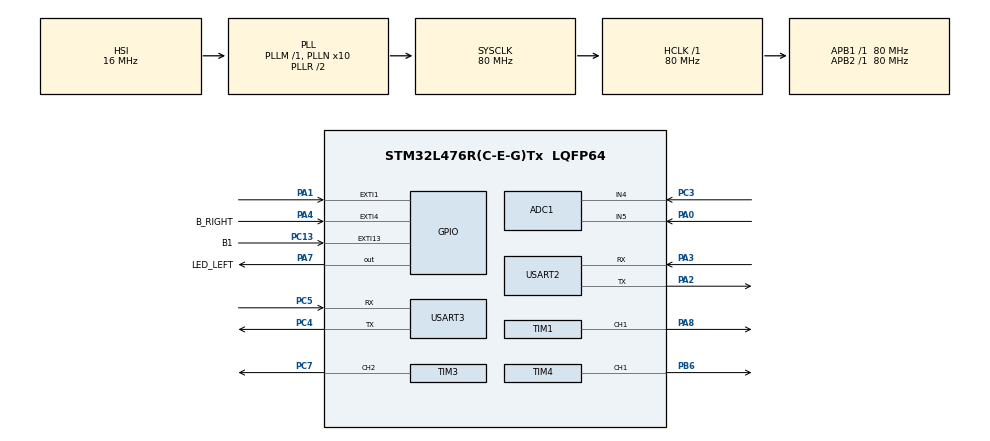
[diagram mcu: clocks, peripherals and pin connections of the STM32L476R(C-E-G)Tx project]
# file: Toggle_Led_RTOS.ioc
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ADC1.Channel-1\#ChannelRegularConversion=ADC_CHANNEL_4
ADC1.ContinuousConvMode=ENABLE
ADC1.NbrOfConversionFlag=1
ADC1.OffsetNumber-1\#ChannelRegularConversion=ADC_OFFSET_NONE
ADC1.Rank-1\#ChannelRegularConversion=1
ADC1.SamplingTime-1\#ChannelRegularConversion=ADC_SAMPLETIME_2CYCLES_5
ADC1.master=1
FREERTOS.Tasks01=defaultTask,24,128,StartDefaultTask,Default,NULL,Dynamic,NULL,NULL
Mcu.Family=STM32L4
Mcu.Name=STM32L476R(C-E-G)Tx
Mcu.Package=LQFP64
NVIC.ADC1_2_IRQn=true\:5\:0\:false\:false\:true\:true\:true\:true\:true
NVIC.EXTI15_10_IRQn=true\:5\:0\:false\:false\:true\:true\:true\:true\:true
NVIC.EXTI1_IRQn=true\:5\:0\:false\:false\:true\:true\:true\:true\:true
NVIC.EXTI4_IRQn=true\:5\:0\:false\:false\:true\:true\:true\:true\:true
NVIC.PriorityGroup=NVIC_PRIORITYGROUP_4
NVIC.USART2_IRQn=true\:5\:0\:false\:false\:true\:true\:true\:true\:true
NVIC.USART3_IRQn=true\:5\:0\:false\:false\:true\:true\:true\:true\:true
PA0.Signal=ADCx_IN5
PA1.Signal=GPXTI1
PA2.Mode=Asynchronous
PA2.Signal=USART2_TX
PA3.Mode=Asynchronous
PA3.Signal=USART2_RX
PA4.GPIO_Label=B_RIGHT
PA4.Signal=GPXTI4
PA7.GPIO_Label=LED_LEFT
PA7.PinState=GPIO_PIN_SET
PA7.Signal=GPIO_Output
PA8.Signal=S_TIM1_CH1
PB6.Signal=S_TIM4_CH1
PC13.GPIO_Label=B1
PC13.Signal=GPXTI13
PC3.Signal=ADCx_IN4
PC4.Mode=Asynchronous
PC4.Signal=USART3_TX
PC5.Mode=Asynchronous
PC5.Signal=USART3_RX
PC7.Signal=S_TIM3_CH2
ProjectManager.HeapSize=0x200
ProjectManager.StackSize=0x400
ProjectManager.TargetToolchain=STM32CubeIDE
RCC.ADCFreq_Value=64000000
RCC.AHBFreq_Value=80000000
RCC.APB1Freq_Value=80000000
RCC.APB1TimFreq_Value=80000000
RCC.APB2Freq_Value=80000000
RCC.APB2TimFreq_Value=80000000
RCC.CortexFreq_Value=80000000
RCC.HCLKFreq_Value=80000000
RCC.HSE_VALUE=8000000
RCC.HSI_VALUE=16000000
RCC.LSE_VALUE=32768
RCC.MSI_VALUE=4000000
RCC.PLLN=10
RCC.PLLSourceVirtual=RCC_PLLSOURCE_HSI
RCC.SYSCLKFreq_VALUE=80000000
RCC.SYSCLKSource=RCC_SYSCLKSOURCE_PLLCLK
RCC.USBFreq_Value=64000000
RCC.VCOOutputFreq_Value=160000000
SH.ADCx_IN4.0=ADC1_IN4,IN4-Single-Ended
SH.ADCx_IN5.0=ADC1_IN5,IN5-Single-Ended
SH.S_TIM1_CH1.0=TIM1_CH1,PWM Generation1 CH1
SH.S_TIM3_CH2.0=TIM3_CH2,PWM Generation2 CH2
SH.S_TIM4_CH1.0=TIM4_CH1,PWM Generation1 CH1
TIM1.Channel-PWM\ Generation1\ CH1=TIM_CHANNEL_1
TIM16.Period=10000-1
TIM16.Prescaler=8000-1
TIM3.Channel-PWM\ Generation2\ CH2=TIM_CHANNEL_2
TIM4.Channel-PWM\ Generation1\ CH1=TIM_CHANNEL_1
USART2.VirtualMode-Asynchronous=VM_ASYNC
USART3.VirtualMode-Asynchronous=VM_ASYNC
VP_FREERTOS_VS_CMSIS_V2.Mode=CMSIS_V2
VP_TIM16_VS_ClockSourceINT.Mode=Enable_Timer
board=custom

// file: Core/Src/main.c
/* USER CODE BEGIN Header */
/**
  ******************************************************************************
  * @file           : main.c
  * @brief          : Main program body
  ******************************************************************************
  * @attention
  *
  * Copyright (c) 2024 STMicroelectronics.
  * All rights reserved.
  *
  * This software is licensed under terms that can be found in the LICENSE file
  * in the root directory of this software component.
  * If no LICENSE file comes with this software, it is provided AS-IS.
  *
  ******************************************************************************
  */
/* USER CODE END Header */
#include "main.h"
#include "cmsis_os.h"

/* USER CODE BEGIN Includes */
#include "string.h"

#include <stdio.h>
/* USER CODE END Includes */

/* USER CODE BEGIN PD */

#define REFERENCE_VOLTAGE 1.6f
#define NUM_INTERVALS     8

// Si quieres que sea variable en tiempo de ejecución:
// static float referenceVoltage = 2.5f;

/* USER CODE END PD */

/* USER CODE BEGIN PM */
/* Handles de periféricos */
ADC_HandleTypeDef hadc1;
UART_HandleTypeDef huart2;

/* USER CODE END PM */

ADC_HandleTypeDef hadc1;

TIM_HandleTypeDef htim1;
TIM_HandleTypeDef htim3;
TIM_HandleTypeDef htim4;
TIM_HandleTypeDef htim16;

UART_HandleTypeDef huart2;
UART_HandleTypeDef huart3;

/* Definitions for defaultTask */
osThreadId_t defaultTaskHandle;
const osThreadAttr_t defaultTask_attributes = {
  .name = "defaultTask",
  .stack_size = 128 * 4,
  .priority = (osPriority_t) osPriorityNormal,
};

void SystemClock_Config(void);
static void MX_GPIO_Init(void);
static void MX_ADC1_Init(void);
static void MX_USART2_UART_Init(void);
static void MX_USART3_UART_Init(void);
static void MX_TIM4_Init(void);
static void MX_TIM16_Init(void);
static void MX_TIM3_Init(void);
static void MX_TIM1_Init(void);
void StartDefaultTask(void *argument);

/* USER CODE BEGIN PFP */

/* Prototipos de funciones */
void HAL_GPIO_EXTI_Callback(uint16_t GPIO_Pin);
void Read_ADC(uint32_t *adc_value, float *voltage);
void Update_PWM_DutyCycle(float voltage);

/* Declaración de tareas */
void Task_ADC_Read_And_Update_PWM(void *argument);

/* Variables globales */
volatile uint8_t adc_task_active = 0; // Bandera para controlar el estado de la tarea (1 = activa, 0 = inactiva)
volatile uint32_t debounce_time = 0;  // Tiempo para el filtro de rebote

/* Declaración del handle de la tarea */
osThreadId_t adc_task_handle;

/* USER CODE END PFP */

int main(void)
{

  /* MCU Configuration--------------------------------------------------------*/

  /* Reset of all peripherals, Initializes the Flash interface and the Systick. */
  HAL_Init();

  /* Configure the system clock */
  SystemClock_Config();

  /* Initialize all configured peripherals */
  MX_GPIO_Init();
  MX_ADC1_Init();
  MX_USART2_UART_Init();
  MX_USART3_UART_Init();
  MX_TIM4_Init();
  MX_TIM3_Init();
  MX_TIM16_Init();
  MX_TIM1_Init();

  /* Iniciar PWM en TIM4 Channel 1 */
  HAL_TIM_PWM_Start(&htim3, TIM_CHANNEL_2);
  HAL_TIM_PWM_Start(&htim1, TIM_CHANNEL_1);

  /* Inicialización de FreeRTOS */
  osKernelInitialize();

  /* Crear tarea para lectura y actualización del PWM */
  adc_task_handle = osThreadNew(Task_ADC_Read_And_Update_PWM, NULL, NULL);

  /* Create the thread(s) */
  /* creation of defaultTask */

  /* Start scheduler */
  osKernelStart();

  /* We should never get here as control is now taken by the scheduler */

  /* Infinite loop */
  while (1)
  {

  }
}

/* Tarea: Leer ADC, actualizar PWM y transmitir voltaje */
void Task_ADC_Read_And_Update_PWM(void *argument)
{
    uint32_t adc_value;
    float voltage;
    char msg[50];

    for (;;)
    {
        if (adc_task_active) // Verificar si la tarea está activa
        {
            // Leer ADC y calcular voltaje
            Read_ADC(&adc_value, &voltage);

            // Actualizar ciclo útil del PWM según la diferencia
            Update_PWM_DutyCycle(voltage);

            voltage= (voltage/5.2)*100;

            // Transmitir por UART
            snprintf(msg, sizeof(msg), "Voltage: %.2f C\r\n", voltage);
            HAL_UART_Transmit(&huart2, (uint8_t *)msg, strlen(msg), HAL_MAX_DELAY);

            // Esperar 300 ms
            osDelay(300);
        }
        else
        {
            // Si la tarea no está activa, apagar PWM (duty = 0)
            __HAL_TIM_SET_COMPARE(&htim3, TIM_CHANNEL_2, 0);
            __HAL_TIM_SET_COMPARE(&htim1, TIM_CHANNEL_1, 0);
            osDelay(100);
        }
    }
}

/* Callback de la interrupción del botón */
void HAL_GPIO_EXTI_Callback(uint16_t GPIO_Pin)
{
    if (GPIO_Pin == GPIO_PIN_1) // Botón conectado al pin GPIO_PIN_1
    {
        uint32_t current_time = HAL_GetTick();
        if ((current_time - debounce_time) >= 200) // Filtro de rebote con 100 ms
        {
            debounce_time = current_time; // Actualizar tiempo de la última pulsación

            if (adc_task_active)
            {
                // Detener la tarea
                adc_task_active = 0;
                HAL_UART_Transmit(&huart2, (uint8_t *)"ADC Stopped\r\n", 13, HAL_MAX_DELAY);
            }
            else
            {
                // Activar la tarea
                adc_task_active = 1;
                HAL_UART_Transmit(&huart2, (uint8_t *)"ADC Started\r\n", 13, HAL_MAX_DELAY);
            }
        }
    }
}

/* Leer ADC y calcular voltaje */
void Read_ADC(uint32_t *adc_value, float *voltage)
{
    HAL_ADC_Start(&hadc1);
    if (HAL_ADC_PollForConversion(&hadc1, 100) == HAL_OK)
    {
        *adc_value = HAL_ADC_GetValue(&hadc1);
        *voltage = (*adc_value * 3.3) / 4095.0; // Conversión a voltaje
    }
    HAL_ADC_Stop(&hadc1);
}

/* Actualizar el ciclo útil del PWM de forma “paramétrica” */
/* Ajusta aquí la referencia y la cantidad de intervalos */

void Update_PWM_DutyCycle(float voltage)
{
    // 1) Calcular la diferencia con la referencia
    float diff = REFERENCE_VOLTAGE-voltage;

    // 2) Calcular el tamaño de cada intervalo
    float intervalSize = REFERENCE_VOLTAGE / (float)NUM_INTERVALS;
    // Si REFERENCE_VOLTAGE = 2.5, intervalSize = 2.5/8 = 0.3125

    // 3) Definir el duty cycle (0..1) según el rango de 'diff'
    float dutyPercent;

    if (diff>=0){
        __HAL_TIM_SET_COMPARE(&htim1, TIM_CHANNEL_1, 0);

        // Comparamos de mayor a menor:
        if (diff >= intervalSize * 7)
        {
            // Ej. diff >= 2.1875 => muy por debajo de la referencia => PWM alto
            dutyPercent = 0.99f;
        }
        else if (diff >= intervalSize * 6) // [1.875, 2.1875)
        {
            dutyPercent = 0.99f;
        }
        else if (diff >= intervalSize * 5) // [1.5625, 1.875)
        {
            dutyPercent = 0.95f;
        }
        else if (diff >= intervalSize * 4) // [1.25, 1.5625)
        {
            dutyPercent = 0.85f;
        }
        else if (diff >= intervalSize * 3) // [0.9375, 1.25)
        {
            dutyPercent = 0.70f;
        }
        else if (diff >= intervalSize * 2) // [0.625, 0.9375)
        {
            dutyPercent = 0.65f;
        }
        else if (diff >= intervalSize * 1) // [0.3125, 0.625)
        {
            dutyPercent = 0.40f;
        }
        else if (diff >= intervalSize * 0) // [0.0, 0.3125)
        {
            dutyPercent = 0.15f;
        }
        else
        {
            // diff < 0 => el voltaje está por encima de la referencia
            dutyPercent = 0.0f;
        }

        // 4) Convierte el duty cycle a valor de CCR (Registro de Comparación)
        uint32_t period = htim3.Init.Period;
        uint32_t pwm_value = (uint32_t)(dutyPercent * (float)period);

        // 5) Actualiza el CCR para generar el PWM
        __HAL_TIM_SET_COMPARE(&htim3, TIM_CHANNEL_2, pwm_value);

    }else{
        __HAL_TIM_SET_COMPARE(&htim3, TIM_CHANNEL_2, 0);

    	diff = voltage- REFERENCE_VOLTAGE;

        // Comparamos de mayor a menor:
        if (diff >= intervalSize * 7)
        {
            // Ej. diff >= 2.1875 => muy por debajo de la referencia => PWM alto
            dutyPercent = 0.99f;
        }
        else if (diff >= intervalSize * 6) // [1.875, 2.1875)
        {
            dutyPercent = 0.99f;
        }
        else if (diff >= intervalSize * 5) // [1.5625, 1.875)
        {
            dutyPercent = 0.95f;
        }
        else if (diff >= intervalSize * 4) // [1.25, 1.5625)
        {
            dutyPercent = 0.85f;
        }
        else if (diff >= intervalSize * 3) // [0.9375, 1.25)
        {
            dutyPercent = 0.65f;
        }
        else if (diff >= intervalSize * 2) // [0.625, 0.9375)
        {
            dutyPercent = 0.55f;
        }
        else if (diff >= intervalSize * 1) // [0.3125, 0.625)
        {
            dutyPercent = 0.40f;
        }
        else if (diff >= intervalSize * 0) // [0.0, 0.3125)
        {
            dutyPercent = 0.25f;
        }
        else
        {
            // diff < 0 => el voltaje está por encima de la referencia
            dutyPercent = 0.0f;
        }

        // 4) Convierte el duty cycle a valor de CCR (Registro de Comparación)
        uint32_t period = htim1.Init.Period;
        uint32_t pwm_value = (uint32_t)(dutyPercent * (float)period);

        // 5) Actualiza el CCR para generar el PWM
        __HAL_TIM_SET_COMPARE(&htim1, TIM_CHANNEL_1, pwm_value);

    }

}

void SystemClock_Config(void)
{
  RCC_OscInitTypeDef RCC_OscInitStruct = {0};
  RCC_ClkInitTypeDef RCC_ClkInitStruct = {0};

  /** Configure the main internal regulator output voltage
  */
  if (HAL_PWREx_ControlVoltageScaling(PWR_REGULATOR_VOLTAGE_SCALE1) != HAL_OK)
  {
    Error_Handler();
  }

  /** Initializes the RCC Oscillators according to the specified parameters
  * in the RCC_OscInitTypeDef structure.
  */
  RCC_OscInitStruct.OscillatorType = RCC_OSCILLATORTYPE_HSI;
  RCC_OscInitStruct.HSIState = RCC_HSI_ON;
  RCC_OscInitStruct.HSICalibrationValue = RCC_HSICALIBRATION_DEFAULT;
  RCC_OscInitStruct.PLL.PLLState = RCC_PLL_ON;
  RCC_OscInitStruct.PLL.PLLSource = RCC_PLLSOURCE_HSI;
  RCC_OscInitStruct.PLL.PLLM = 1;
  RCC_OscInitStruct.PLL.PLLN = 10;
  RCC_OscInitStruct.PLL.PLLP = RCC_PLLP_DIV7;
  RCC_OscInitStruct.PLL.PLLQ = RCC_PLLQ_DIV2;
  RCC_OscInitStruct.PLL.PLLR = RCC_PLLR_DIV2;
  if (HAL_RCC_OscConfig(&RCC_OscInitStruct) != HAL_OK)
  {
    Error_Handler();
  }

  /** Initializes the CPU, AHB and APB buses clocks
  */
  RCC_ClkInitStruct.ClockType = RCC_CLOCKTYPE_HCLK|RCC_CLOCKTYPE_SYSCLK
                              |RCC_CLOCKTYPE_PCLK1|RCC_CLOCKTYPE_PCLK2;
  RCC_ClkInitStruct.SYSCLKSource = RCC_SYSCLKSOURCE_PLLCLK;
  RCC_ClkInitStruct.AHBCLKDivider = RCC_SYSCLK_DIV1;
  RCC_ClkInitStruct.APB1CLKDivider = RCC_HCLK_DIV1;
  RCC_ClkInitStruct.APB2CLKDivider = RCC_HCLK_DIV1;

  if (HAL_RCC_ClockConfig(&RCC_ClkInitStruct, FLASH_LATENCY_4) != HAL_OK)
  {
    Error_Handler();
  }
}

static void MX_ADC1_Init(void)
{

  ADC_MultiModeTypeDef multimode = {0};
  ADC_ChannelConfTypeDef sConfig = {0};

  /** Common config
  */
  hadc1.Instance = ADC1;
  hadc1.Init.ClockPrescaler = ADC_CLOCK_ASYNC_DIV1;
  hadc1.Init.Resolution = ADC_RESOLUTION_12B;
  hadc1.Init.DataAlign = ADC_DATAALIGN_RIGHT;
  hadc1.Init.ScanConvMode = ADC_SCAN_DISABLE;
  hadc1.Init.EOCSelection = ADC_EOC_SINGLE_CONV;
  hadc1.Init.LowPowerAutoWait = DISABLE;
  hadc1.Init.ContinuousConvMode = ENABLE;
  hadc1.Init.NbrOfConversion = 1;
  hadc1.Init.DiscontinuousConvMode = DISABLE;
  hadc1.Init.ExternalTrigConv = ADC_SOFTWARE_START;
  hadc1.Init.ExternalTrigConvEdge = ADC_EXTERNALTRIGCONVEDGE_NONE;
  hadc1.Init.DMAContinuousRequests = DISABLE;
  hadc1.Init.Overrun = ADC_OVR_DATA_PRESERVED;
  hadc1.Init.OversamplingMode = DISABLE;
  if (HAL_ADC_Init(&hadc1) != HAL_OK)
  {
    Error_Handler();
  }

  /** Configure the ADC multi-mode
  */
  multimode.Mode = ADC_MODE_INDEPENDENT;
  if (HAL_ADCEx_MultiModeConfigChannel(&hadc1, &multimode) != HAL_OK)
  {
    Error_Handler();
  }

  /** Configure Regular Channel
  */
  sConfig.Channel = ADC_CHANNEL_4;
  sConfig.Rank = ADC_REGULAR_RANK_1;
  sConfig.SamplingTime = ADC_SAMPLETIME_2CYCLES_5;
  sConfig.SingleDiff = ADC_SINGLE_ENDED;
  sConfig.OffsetNumber = ADC_OFFSET_NONE;
  sConfig.Offset = 0;
  if (HAL_ADC_ConfigChannel(&hadc1, &sConfig) != HAL_OK)
  {
    Error_Handler();
  }

}

static void MX_TIM1_Init(void)
{

  TIM_MasterConfigTypeDef sMasterConfig = {0};
  TIM_OC_InitTypeDef sConfigOC = {0};
  TIM_BreakDeadTimeConfigTypeDef sBreakDeadTimeConfig = {0};

  htim1.Instance = TIM1;
  htim1.Init.Prescaler = 0;
  htim1.Init.CounterMode = TIM_COUNTERMODE_UP;
  htim1.Init.Period = 65535;
  htim1.Init.ClockDivision = TIM_CLOCKDIVISION_DIV1;
  htim1.Init.RepetitionCounter = 0;
  htim1.Init.AutoReloadPreload = TIM_AUTORELOAD_PRELOAD_DISABLE;
  if (HAL_TIM_PWM_Init(&htim1) != HAL_OK)
  {
    Error_Handler();
  }
  sMasterConfig.MasterOutputTrigger = TIM_TRGO_RESET;
  sMasterConfig.MasterOutputTrigger2 = TIM_TRGO2_RESET;
  sMasterConfig.MasterSlaveMode = TIM_MASTERSLAVEMODE_DISABLE;
  if (HAL_TIMEx_MasterConfigSynchronization(&htim1, &sMasterConfig) != HAL_OK)
  {
    Error_Handler();
  }
  sConfigOC.OCMode = TIM_OCMODE_PWM1;
  sConfigOC.Pulse = 0;
  sConfigOC.OCPolarity = TIM_OCPOLARITY_HIGH;
  sConfigOC.OCNPolarity = TIM_OCNPOLARITY_HIGH;
  sConfigOC.OCFastMode = TIM_OCFAST_DISABLE;
  sConfigOC.OCIdleState = TIM_OCIDLESTATE_RESET;
  sConfigOC.OCNIdleState = TIM_OCNIDLESTATE_RESET;
  if (HAL_TIM_PWM_ConfigChannel(&htim1, &sConfigOC, TIM_CHANNEL_1) != HAL_OK)
  {
    Error_Handler();
  }
  sBreakDeadTimeConfig.OffStateRunMode = TIM_OSSR_DISABLE;
  sBreakDeadTimeConfig.OffStateIDLEMode = TIM_OSSI_DISABLE;
  sBreakDeadTimeConfig.LockLevel = TIM_LOCKLEVEL_OFF;
  sBreakDeadTimeConfig.DeadTime = 0;
  sBreakDeadTimeConfig.BreakState = TIM_BREAK_DISABLE;
  sBreakDeadTimeConfig.BreakPolarity = TIM_BREAKPOLARITY_HIGH;
  sBreakDeadTimeConfig.BreakFilter = 0;
  sBreakDeadTimeConfig.Break2State = TIM_BREAK2_DISABLE;
  sBreakDeadTimeConfig.Break2Polarity = TIM_BREAK2POLARITY_HIGH;
  sBreakDeadTimeConfig.Break2Filter = 0;
  sBreakDeadTimeConfig.AutomaticOutput = TIM_AUTOMATICOUTPUT_DISABLE;
  if (HAL_TIMEx_ConfigBreakDeadTime(&htim1, &sBreakDeadTimeConfig) != HAL_OK)
  {
    Error_Handler();
  }
  HAL_TIM_MspPostInit(&htim1);

}

static void MX_TIM3_Init(void)
{

  TIM_MasterConfigTypeDef sMasterConfig = {0};
  TIM_OC_InitTypeDef sConfigOC = {0};

  htim3.Instance = TIM3;
  htim3.Init.Prescaler = 0;
  htim3.Init.CounterMode = TIM_COUNTERMODE_UP;
  htim3.Init.Period = 65535;
  htim3.Init.ClockDivision = TIM_CLOCKDIVISION_DIV1;
  htim3.Init.AutoReloadPreload = TIM_AUTORELOAD_PRELOAD_DISABLE;
  if (HAL_TIM_PWM_Init(&htim3) != HAL_OK)
  {
    Error_Handler();
  }
  sMasterConfig.MasterOutputTrigger = TIM_TRGO_RESET;
  sMasterConfig.MasterSlaveMode = TIM_MASTERSLAVEMODE_DISABLE;
  if (HAL_TIMEx_MasterConfigSynchronization(&htim3, &sMasterConfig) != HAL_OK)
  {
    Error_Handler();
  }
  sConfigOC.OCMode = TIM_OCMODE_PWM1;
  sConfigOC.Pulse = 0;
  sConfigOC.OCPolarity = TIM_OCPOLARITY_HIGH;
  sConfigOC.OCFastMode = TIM_OCFAST_DISABLE;
  if (HAL_TIM_PWM_ConfigChannel(&htim3, &sConfigOC, TIM_CHANNEL_2) != HAL_OK)
  {
    Error_Handler();
  }
  HAL_TIM_MspPostInit(&htim3);

}

static void MX_TIM4_Init(void)
{

  TIM_MasterConfigTypeDef sMasterConfig = {0};
  TIM_OC_InitTypeDef sConfigOC = {0};

  htim4.Instance = TIM4;
  htim4.Init.Prescaler = 0;
  htim4.Init.CounterMode = TIM_COUNTERMODE_UP;
  htim4.Init.Period = 65535;
  htim4.Init.ClockDivision = TIM_CLOCKDIVISION_DIV1;
  htim4.Init.AutoReloadPreload = TIM_AUTORELOAD_PRELOAD_DISABLE;
  if (HAL_TIM_PWM_Init(&htim4) != HAL_OK)
  {
    Error_Handler();
  }
  sMasterConfig.MasterOutputTrigger = TIM_TRGO_RESET;
  sMasterConfig.MasterSlaveMode = TIM_MASTERSLAVEMODE_DISABLE;
  if (HAL_TIMEx_MasterConfigSynchronization(&htim4, &sMasterConfig) != HAL_OK)
  {
    Error_Handler();
  }
  sConfigOC.OCMode = TIM_OCMODE_PWM1;
  sConfigOC.Pulse = 0;
  sConfigOC.OCPolarity = TIM_OCPOLARITY_HIGH;
  sConfigOC.OCFastMode = TIM_OCFAST_DISABLE;
  if (HAL_TIM_PWM_ConfigChannel(&htim4, &sConfigOC, TIM_CHANNEL_1) != HAL_OK)
  {
    Error_Handler();
  }
  HAL_TIM_MspPostInit(&htim4);

}

static void MX_TIM16_Init(void)
{

  htim16.Instance = TIM16;
  htim16.Init.Prescaler = 8000-1;
  htim16.Init.CounterMode = TIM_COUNTERMODE_UP;
  htim16.Init.Period = 10000-1;
  htim16.Init.ClockDivision = TIM_CLOCKDIVISION_DIV1;
  htim16.Init.RepetitionCounter = 0;
  htim16.Init.AutoReloadPreload = TIM_AUTORELOAD_PRELOAD_DISABLE;
  if (HAL_TIM_Base_Init(&htim16) != HAL_OK)
  {
    Error_Handler();
  }

}

static void MX_USART2_UART_Init(void)
{

  huart2.Instance = USART2;
  huart2.Init.BaudRate = 115200;
  huart2.Init.WordLength = UART_WORDLENGTH_8B;
  huart2.Init.StopBits = UART_STOPBITS_1;
  huart2.Init.Parity = UART_PARITY_NONE;
  huart2.Init.Mode = UART_MODE_TX_RX;
  huart2.Init.HwFlowCtl = UART_HWCONTROL_NONE;
  huart2.Init.OverSampling = UART_OVERSAMPLING_16;
  huart2.Init.OneBitSampling = UART_ONE_BIT_SAMPLE_DISABLE;
  huart2.AdvancedInit.AdvFeatureInit = UART_ADVFEATURE_NO_INIT;
  if (HAL_UART_Init(&huart2) != HAL_OK)
  {
    Error_Handler();
  }

}

static void MX_USART3_UART_Init(void)
{

  huart3.Instance = USART3;
  huart3.Init.BaudRate = 115200;
  huart3.Init.WordLength = UART_WORDLENGTH_8B;
  huart3.Init.StopBits = UART_STOPBITS_1;
  huart3.Init.Parity = UART_PARITY_NONE;
  huart3.Init.Mode = UART_MODE_TX_RX;
  huart3.Init.HwFlowCtl = UART_HWCONTROL_NONE;
  huart3.Init.OverSampling = UART_OVERSAMPLING_16;
  huart3.Init.OneBitSampling = UART_ONE_BIT_SAMPLE_DISABLE;
  huart3.AdvancedInit.AdvFeatureInit = UART_ADVFEATURE_NO_INIT;
  if (HAL_UART_Init(&huart3) != HAL_OK)
  {
    Error_Handler();
  }

}

static void MX_GPIO_Init(void)
{
  GPIO_InitTypeDef GPIO_InitStruct = {0};

  /* GPIO Ports Clock Enable */
  __HAL_RCC_GPIOC_CLK_ENABLE();
  __HAL_RCC_GPIOA_CLK_ENABLE();
  __HAL_RCC_GPIOB_CLK_ENABLE();

  /*Configure GPIO pin Output Level */
  HAL_GPIO_WritePin(LED_LEFT_GPIO_Port, LED_LEFT_Pin, GPIO_PIN_SET);

  /*Configure GPIO pin : B1_Pin */
  GPIO_InitStruct.Pin = B1_Pin;
  GPIO_InitStruct.Mode = GPIO_MODE_IT_RISING;
  GPIO_InitStruct.Pull = GPIO_NOPULL;
  HAL_GPIO_Init(B1_GPIO_Port, &GPIO_InitStruct);

  /*Configure GPIO pins : PA1 B_RIGHT_Pin */
  GPIO_InitStruct.Pin = GPIO_PIN_1|B_RIGHT_Pin;
  GPIO_InitStruct.Mode = GPIO_MODE_IT_RISING;
  GPIO_InitStruct.Pull = GPIO_NOPULL;
  HAL_GPIO_Init(GPIOA, &GPIO_InitStruct);

  /*Configure GPIO pin : LED_LEFT_Pin */
  GPIO_InitStruct.Pin = LED_LEFT_Pin;
  GPIO_InitStruct.Mode = GPIO_MODE_OUTPUT_PP;
  GPIO_InitStruct.Pull = GPIO_NOPULL;
  GPIO_InitStruct.Speed = GPIO_SPEED_FREQ_LOW;
  HAL_GPIO_Init(LED_LEFT_GPIO_Port, &GPIO_InitStruct);

  /* EXTI interrupt init*/
  HAL_NVIC_SetPriority(EXTI1_IRQn, 5, 0);
  HAL_NVIC_EnableIRQ(EXTI1_IRQn);

  HAL_NVIC_SetPriority(EXTI4_IRQn, 5, 0);
  HAL_NVIC_EnableIRQ(EXTI4_IRQn);

  HAL_NVIC_SetPriority(EXTI15_10_IRQn, 5, 0);
  HAL_NVIC_EnableIRQ(EXTI15_10_IRQn);

}

void StartDefaultTask(void *argument)
{
  for(;;)
  {
    osDelay(1);
  }
}

void Error_Handler(void)
{
  __disable_irq();
  while (1)
  {
  }
}

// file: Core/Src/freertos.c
/* USER CODE BEGIN Header */
/**
  ******************************************************************************
  * File Name          : freertos.c
  * Description        : Code for freertos applications
  ******************************************************************************
  * @attention
  *
  * Copyright (c) 2024 STMicroelectronics.
  * All rights reserved.
  *
  * This software is licensed under terms that can be found in the LICENSE file
  * in the root directory of this software component.
  * If no LICENSE file comes with this software, it is provided AS-IS.
  *
  ******************************************************************************
  */
/* USER CODE END Header */

#include "FreeRTOS.h"
#include "task.h"
#include "main.h"

/* USER CODE BEGIN FunctionPrototypes */

void MX_FREERTOS_Init(void)
{
    // Aquí puedes crear tareas, inicializar colas, semáforos, etc.

    // Por ahora, deja esto vacío para resolver el error.
}

/* USER CODE END FunctionPrototypes */
